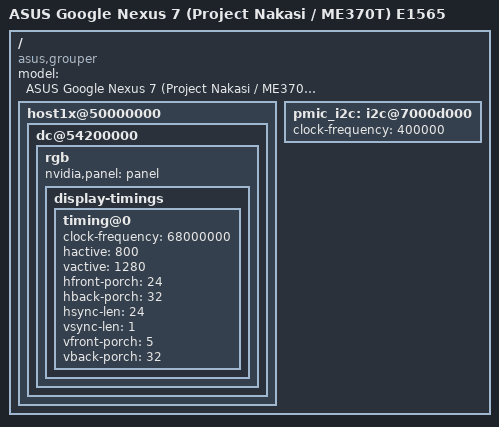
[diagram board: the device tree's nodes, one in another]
// SPDX-License-Identifier: GPL-2.0-or-later
/dts-v1/;

#include <dt-bindings/input/gpio-keys.h>
#include <dt-bindings/input/linux-event-codes.h>

#include "tegra30-asus-grouper-common.dtsi"

/ {
	model = "ASUS Google Nexus 7 (Project Nakasi / ME370T) E1565";
	compatible = "asus,grouper", "nvidia,tegra30";

	host1x@50000000 {
		status = "okay";
		dc@54200000 {
			status = "okay";
			rgb {
				status = "okay";

				nvidia,panel = <&panel>;

				display-timings {
					timing@0 {
						/* 1280x800@60Hz */
						clock-frequency = <68000000>;
						hactive = <800>;
						vactive = <1280>;
						hfront-porch = <24>;
						hback-porch = <32>;
						hsync-len = <24>;
						vsync-len = <1>;
						vfront-porch = <5>;
						vback-porch = <32>;
					};
				};
			};
		};
	};

	pmic_i2c: i2c@7000d000 {
		status = "okay";
		clock-frequency = <400000>;
	};
};
